# ESP32-S31 register map
Vendor: ESPRESSIF SYSTEMS (SHANGHAI) CO., LTD.; Series: ESP32 S-Series; File version: 1
CPU: RV32IMAFC r0p0, little endian, no MPU, FPU, 0 interrupt priority bits
Address unit: 32 bits
Registers are 32-bit, read-write, reset 0x0 unless marked. A register's access mark holds for its fields unless they carry their own. Offsets are from the block's base; [hi:lo] are bit positions.

## LP_PERI_PMS — LP_PERI_PMS Peripheral
Base 0x20706000
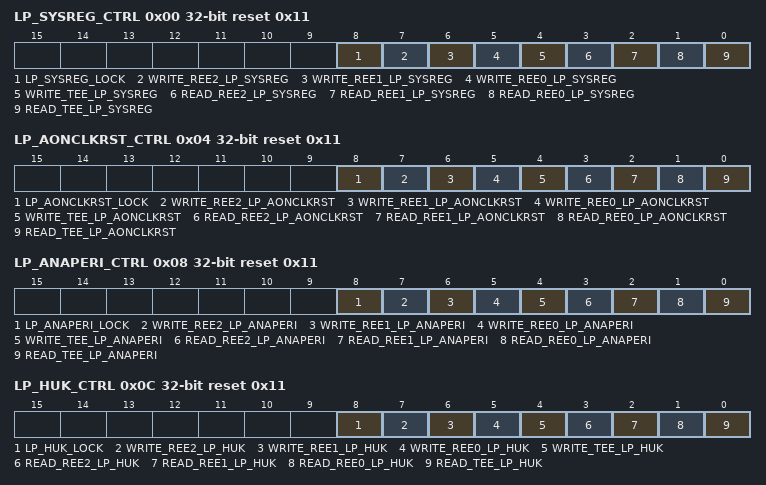
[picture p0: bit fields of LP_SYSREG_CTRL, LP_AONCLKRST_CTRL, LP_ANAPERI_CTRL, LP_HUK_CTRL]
0x00 LP_SYSREG_CTRL reset 0x11 — lp_sysreg read/write control register
  [8] LP_SYSREG_LOCK — Set 1 to lock lp_sysreg peri_apm configuration
  [7] WRITE_REE2_LP_SYSREG — Configures lp_sysreg registers write permission in ree2 mode.\\ 0: can not be write \\ 1: can be write \\
  [6] WRITE_REE1_LP_SYSREG — Configures lp_sysreg registers write permission in ree1 mode.\\ 0: can not be write \\ 1: can be write \\
  [5] WRITE_REE0_LP_SYSREG — Configures lp_sysreg registers write permission in ree0 mode.\\ 0: can not be write \\ 1: can be write \\
  [4] WRITE_TEE_LP_SYSREG — Configures lp_sysreg registers write permission in tee mode.\\ 0: can not be write \\ 1: can be write \\
  [3] READ_REE2_LP_SYSREG — Configures lp_sysreg registers read permission in ree2 mode.\\ 0: can not be read \\ 1: can be read \\
  [2] READ_REE1_LP_SYSREG — Configures lp_sysreg registers read permission in ree1 mode.\\ 0: can not be read \\ 1: can be read \\
  [1] READ_REE0_LP_SYSREG — Configures lp_sysreg registers read permission in ree0 mode.\\ 0: can not be read \\ 1: can be read \\
  [0] READ_TEE_LP_SYSREG — Configures lp_sysreg registers read permission in tee mode.\\ 0: can not be read \\ 1: can be read \\
0x04 LP_AONCLKRST_CTRL reset 0x11 — lp_aonclkrst read/write control register
  [8] LP_AONCLKRST_LOCK — Set 1 to lock lp_aonclkrst peri_apm configuration
  [7] WRITE_REE2_LP_AONCLKRST — Configures lp_aonclkrst registers write permission in ree2 mode.\\ 0: can not be write \\ 1: can be write \\
  [6] WRITE_REE1_LP_AONCLKRST — Configures lp_aonclkrst registers write permission in ree1 mode.\\ 0: can not be write \\ 1: can be write \\
  [5] WRITE_REE0_LP_AONCLKRST — Configures lp_aonclkrst registers write permission in ree0 mode.\\ 0: can not be write \\ 1: can be write \\
  [4] WRITE_TEE_LP_AONCLKRST — Configures lp_aonclkrst registers write permission in tee mode.\\ 0: can not be write \\ 1: can be write \\
  [3] READ_REE2_LP_AONCLKRST — Configures lp_aonclkrst registers read permission in ree2 mode.\\ 0: can not be read \\ 1: can be read \\
  [2] READ_REE1_LP_AONCLKRST — Configures lp_aonclkrst registers read permission in ree1 mode.\\ 0: can not be read \\ 1: can be read \\
  [1] READ_REE0_LP_AONCLKRST — Configures lp_aonclkrst registers read permission in ree0 mode.\\ 0: can not be read \\ 1: can be read \\
  [0] READ_TEE_LP_AONCLKRST — Configures lp_aonclkrst registers read permission in tee mode.\\ 0: can not be read \\ 1: can be read \\
0x08 LP_ANAPERI_CTRL reset 0x11 — lp_anaperi read/write control register
  [8] LP_ANAPERI_LOCK — Set 1 to lock lp_anaperi peri_apm configuration
  [7] WRITE_REE2_LP_ANAPERI — Configures lp_anaperi registers write permission in ree2 mode.\\ 0: can not be write \\ 1: can be write \\
  [6] WRITE_REE1_LP_ANAPERI — Configures lp_anaperi registers write permission in ree1 mode.\\ 0: can not be write \\ 1: can be write \\
  [5] WRITE_REE0_LP_ANAPERI — Configures lp_anaperi registers write permission in ree0 mode.\\ 0: can not be write \\ 1: can be write \\
  [4] WRITE_TEE_LP_ANAPERI — Configures lp_anaperi registers write permission in tee mode.\\ 0: can not be write \\ 1: can be write \\
  [3] READ_REE2_LP_ANAPERI — Configures lp_anaperi registers read permission in ree2 mode.\\ 0: can not be read \\ 1: can be read \\
  [2] READ_REE1_LP_ANAPERI — Configures lp_anaperi registers read permission in ree1 mode.\\ 0: can not be read \\ 1: can be read \\
  [1] READ_REE0_LP_ANAPERI — Configures lp_anaperi registers read permission in ree0 mode.\\ 0: can not be read \\ 1: can be read \\
  [0] READ_TEE_LP_ANAPERI — Configures lp_anaperi registers read permission in tee mode.\\ 0: can not be read \\ 1: can be read \\
0x0C LP_HUK_CTRL reset 0x11 — lp_huk read/write control register
  [8] LP_HUK_LOCK — Set 1 to lock lp_huk peri_apm configuration
  [7] WRITE_REE2_LP_HUK — Configures lp_huk registers write permission in ree2 mode.\\ 0: can not be write \\ 1: can be write \\
  [6] WRITE_REE1_LP_HUK — Configures lp_huk registers write permission in ree1 mode.\\ 0: can not be write \\ 1: can be write \\
  [5] WRITE_REE0_LP_HUK — Configures lp_huk registers write permission in ree0 mode.\\ 0: can not be write \\ 1: can be write \\
  [4] WRITE_TEE_LP_HUK — Configures lp_huk registers write permission in tee mode.\\ 0: can not be write \\ 1: can be write \\
  [3] READ_REE2_LP_HUK — Configures lp_huk registers read permission in ree2 mode.\\ 0: can not be read \\ 1: can be read \\
  [2] READ_REE1_LP_HUK — Configures lp_huk registers read permission in ree1 mode.\\ 0: can not be read \\ 1: can be read \\
  [1] READ_REE0_LP_HUK — Configures lp_huk registers read permission in ree0 mode.\\ 0: can not be read \\ 1: can be read \\
  [0] READ_TEE_LP_HUK — Configures lp_huk registers read permission in tee mode.\\ 0: can not be read \\ 1: can be read \\
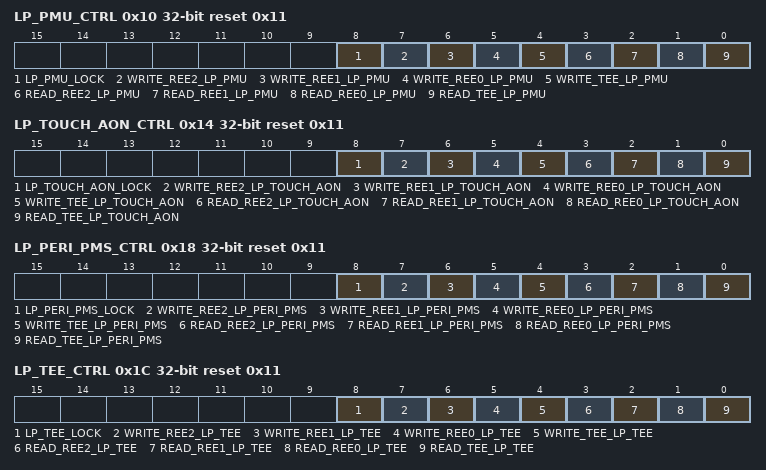
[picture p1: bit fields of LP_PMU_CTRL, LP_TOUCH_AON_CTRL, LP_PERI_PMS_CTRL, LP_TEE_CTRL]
0x10 LP_PMU_CTRL reset 0x11 — lp_pmu read/write control register
  [8] LP_PMU_LOCK — Set 1 to lock lp_pmu peri_apm configuration
  [7] WRITE_REE2_LP_PMU — Configures lp_pmu registers write permission in ree2 mode.\\ 0: can not be write \\ 1: can be write \\
  [6] WRITE_REE1_LP_PMU — Configures lp_pmu registers write permission in ree1 mode.\\ 0: can not be write \\ 1: can be write \\
  [5] WRITE_REE0_LP_PMU — Configures lp_pmu registers write permission in ree0 mode.\\ 0: can not be write \\ 1: can be write \\
  [4] WRITE_TEE_LP_PMU — Configures lp_pmu registers write permission in tee mode.\\ 0: can not be write \\ 1: can be write \\
  [3] READ_REE2_LP_PMU — Configures lp_pmu registers read permission in ree2 mode.\\ 0: can not be read \\ 1: can be read \\
  [2] READ_REE1_LP_PMU — Configures lp_pmu registers read permission in ree1 mode.\\ 0: can not be read \\ 1: can be read \\
  [1] READ_REE0_LP_PMU — Configures lp_pmu registers read permission in ree0 mode.\\ 0: can not be read \\ 1: can be read \\
  [0] READ_TEE_LP_PMU — Configures lp_pmu registers read permission in tee mode.\\ 0: can not be read \\ 1: can be read \\
0x14 LP_TOUCH_AON_CTRL reset 0x11 — lp_touch_aon read/write control register
  [8] LP_TOUCH_AON_LOCK — Set 1 to lock lp_touch_aon peri_apm configuration
  [7] WRITE_REE2_LP_TOUCH_AON — Configures lp_touch_aon registers write permission in ree2 mode.\\ 0: can not be write \\ 1: can be write \\
  [6] WRITE_REE1_LP_TOUCH_AON — Configures lp_touch_aon registers write permission in ree1 mode.\\ 0: can not be write \\ 1: can be write \\
  [5] WRITE_REE0_LP_TOUCH_AON — Configures lp_touch_aon registers write permission in ree0 mode.\\ 0: can not be write \\ 1: can be write \\
  [4] WRITE_TEE_LP_TOUCH_AON — Configures lp_touch_aon registers write permission in tee mode.\\ 0: can not be write \\ 1: can be write \\
  [3] READ_REE2_LP_TOUCH_AON — Configures lp_touch_aon registers read permission in ree2 mode.\\ 0: can not be read \\ 1: can be read \\
  [2] READ_REE1_LP_TOUCH_AON — Configures lp_touch_aon registers read permission in ree1 mode.\\ 0: can not be read \\ 1: can be read \\
  [1] READ_REE0_LP_TOUCH_AON — Configures lp_touch_aon registers read permission in ree0 mode.\\ 0: can not be read \\ 1: can be read \\
  [0] READ_TEE_LP_TOUCH_AON — Configures lp_touch_aon registers read permission in tee mode.\\ 0: can not be read \\ 1: can be read \\
0x18 LP_PERI_PMS_CTRL access per field reset 0x11 — lp_peri_pms read/write control register
  [8] LP_PERI_PMS_LOCK rw — Set 1 to lock lp_peri_pms peri_apm configuration
  [7] WRITE_REE2_LP_PERI_PMS ro — Configures lp_peri_pms registers write permission in ree2 mode.\\ 0: can not be write \\ 1: can be write \\
  [6] WRITE_REE1_LP_PERI_PMS ro — Configures lp_peri_pms registers write permission in ree1 mode.\\ 0: can not be write \\ 1: can be write \\
  [5] WRITE_REE0_LP_PERI_PMS ro — Configures lp_peri_pms registers write permission in ree0 mode.\\ 0: can not be write \\ 1: can be write \\
  [4] WRITE_TEE_LP_PERI_PMS rw — Configures lp_peri_pms registers write permission in tee mode.\\ 0: can not be write \\ 1: can be write \\
  [3] READ_REE2_LP_PERI_PMS ro — Configures lp_peri_pms registers read permission in ree2 mode.\\ 0: can not be read \\ 1: can be read \\
  [2] READ_REE1_LP_PERI_PMS ro — Configures lp_peri_pms registers read permission in ree1 mode.\\ 0: can not be read \\ 1: can be read \\
  [1] READ_REE0_LP_PERI_PMS ro — Configures lp_peri_pms registers read permission in ree0 mode.\\ 0: can not be read \\ 1: can be read \\
  [0] READ_TEE_LP_PERI_PMS rw — Configures lp_peri_pms registers read permission in tee mode.\\ 0: can not be read \\ 1: can be read \\
0x1C LP_TEE_CTRL access per field reset 0x11 — lp_tee read/write control register
  [8] LP_TEE_LOCK rw — Set 1 to lock lp_tee peri_apm configuration
  [7] WRITE_REE2_LP_TEE ro — Configures lp_tee registers write permission in ree2 mode.\\ 0: can not be write \\ 1: can be write \\
  [6] WRITE_REE1_LP_TEE ro — Configures lp_tee registers write permission in ree1 mode.\\ 0: can not be write \\ 1: can be write \\
  [5] WRITE_REE0_LP_TEE ro — Configures lp_tee registers write permission in ree0 mode.\\ 0: can not be write \\ 1: can be write \\
  [4] WRITE_TEE_LP_TEE rw — Configures lp_tee registers write permission in tee mode.\\ 0: can not be write \\ 1: can be write \\
  [3] READ_REE2_LP_TEE ro — Configures lp_tee registers read permission in ree2 mode.\\ 0: can not be read \\ 1: can be read \\
  [2] READ_REE1_LP_TEE ro — Configures lp_tee registers read permission in ree1 mode.\\ 0: can not be read \\ 1: can be read \\
  [1] READ_REE0_LP_TEE ro — Configures lp_tee registers read permission in ree0 mode.\\ 0: can not be read \\ 1: can be read \\
  [0] READ_TEE_LP_TEE rw — Configures lp_tee registers read permission in tee mode.\\ 0: can not be read \\ 1: can be read \\
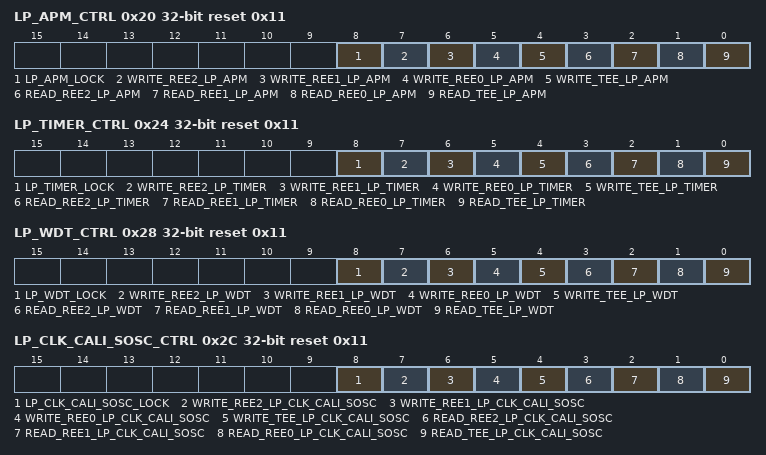
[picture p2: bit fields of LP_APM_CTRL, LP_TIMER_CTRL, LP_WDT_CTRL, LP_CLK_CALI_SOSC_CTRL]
0x20 LP_APM_CTRL access per field reset 0x11 — lp_apm read/write control register
  [8] LP_APM_LOCK rw — Set 1 to lock lp_apm peri_apm configuration
  [7] WRITE_REE2_LP_APM ro — Configures lp_apm registers write permission in ree2 mode.\\ 0: can not be write \\ 1: can be write \\
  [6] WRITE_REE1_LP_APM ro — Configures lp_apm registers write permission in ree1 mode.\\ 0: can not be write \\ 1: can be write \\
  [5] WRITE_REE0_LP_APM ro — Configures lp_apm registers write permission in ree0 mode.\\ 0: can not be write \\ 1: can be write \\
  [4] WRITE_TEE_LP_APM rw — Configures lp_apm registers write permission in tee mode.\\ 0: can not be write \\ 1: can be write \\
  [3] READ_REE2_LP_APM ro — Configures lp_apm registers read permission in ree2 mode.\\ 0: can not be read \\ 1: can be read \\
  [2] READ_REE1_LP_APM ro — Configures lp_apm registers read permission in ree1 mode.\\ 0: can not be read \\ 1: can be read \\
  [1] READ_REE0_LP_APM ro — Configures lp_apm registers read permission in ree0 mode.\\ 0: can not be read \\ 1: can be read \\
  [0] READ_TEE_LP_APM rw — Configures lp_apm registers read permission in tee mode.\\ 0: can not be read \\ 1: can be read \\
0x24 LP_TIMER_CTRL reset 0x11 — lp_timer read/write control register
  [8] LP_TIMER_LOCK — Set 1 to lock lp_timer peri_apm configuration
  [7] WRITE_REE2_LP_TIMER — Configures lp_timer registers write permission in ree2 mode.\\ 0: can not be write \\ 1: can be write \\
  [6] WRITE_REE1_LP_TIMER — Configures lp_timer registers write permission in ree1 mode.\\ 0: can not be write \\ 1: can be write \\
  [5] WRITE_REE0_LP_TIMER — Configures lp_timer registers write permission in ree0 mode.\\ 0: can not be write \\ 1: can be write \\
  [4] WRITE_TEE_LP_TIMER — Configures lp_timer registers write permission in tee mode.\\ 0: can not be write \\ 1: can be write \\
  [3] READ_REE2_LP_TIMER — Configures lp_timer registers read permission in ree2 mode.\\ 0: can not be read \\ 1: can be read \\
  [2] READ_REE1_LP_TIMER — Configures lp_timer registers read permission in ree1 mode.\\ 0: can not be read \\ 1: can be read \\
  [1] READ_REE0_LP_TIMER — Configures lp_timer registers read permission in ree0 mode.\\ 0: can not be read \\ 1: can be read \\
  [0] READ_TEE_LP_TIMER — Configures lp_timer registers read permission in tee mode.\\ 0: can not be read \\ 1: can be read \\
0x28 LP_WDT_CTRL reset 0x11 — lp_wdt read/write control register
  [8] LP_WDT_LOCK — Set 1 to lock lp_wdt peri_apm configuration
  [7] WRITE_REE2_LP_WDT — Configures lp_wdt registers write permission in ree2 mode.\\ 0: can not be write \\ 1: can be write \\
  [6] WRITE_REE1_LP_WDT — Configures lp_wdt registers write permission in ree1 mode.\\ 0: can not be write \\ 1: can be write \\
  [5] WRITE_REE0_LP_WDT — Configures lp_wdt registers write permission in ree0 mode.\\ 0: can not be write \\ 1: can be write \\
  [4] WRITE_TEE_LP_WDT — Configures lp_wdt registers write permission in tee mode.\\ 0: can not be write \\ 1: can be write \\
  [3] READ_REE2_LP_WDT — Configures lp_wdt registers read permission in ree2 mode.\\ 0: can not be read \\ 1: can be read \\
  [2] READ_REE1_LP_WDT — Configures lp_wdt registers read permission in ree1 mode.\\ 0: can not be read \\ 1: can be read \\
  [1] READ_REE0_LP_WDT — Configures lp_wdt registers read permission in ree0 mode.\\ 0: can not be read \\ 1: can be read \\
  [0] READ_TEE_LP_WDT — Configures lp_wdt registers read permission in tee mode.\\ 0: can not be read \\ 1: can be read \\
0x2C LP_CLK_CALI_SOSC_CTRL reset 0x11 — lp_clk_cali_sosc read/write control register
  [8] LP_CLK_CALI_SOSC_LOCK — Set 1 to lock lp_clk_cali_sosc peri_apm configuration
  [7] WRITE_REE2_LP_CLK_CALI_SOSC — Configures lp_clk_cali_sosc registers write permission in ree2 mode.\\ 0: can not be write \\ 1: can be write \\
  [6] WRITE_REE1_LP_CLK_CALI_SOSC — Configures lp_clk_cali_sosc registers write permission in ree1 mode.\\ 0: can not be write \\ 1: can be write \\
  [5] WRITE_REE0_LP_CLK_CALI_SOSC — Configures lp_clk_cali_sosc registers write permission in ree0 mode.\\ 0: can not be write \\ 1: can be write \\
  [4] WRITE_TEE_LP_CLK_CALI_SOSC — Configures lp_clk_cali_sosc registers write permission in tee mode.\\ 0: can not be write \\ 1: can be write \\
  [3] READ_REE2_LP_CLK_CALI_SOSC — Configures lp_clk_cali_sosc registers read permission in ree2 mode.\\ 0: can not be read \\ 1: can be read \\
  [2] READ_REE1_LP_CLK_CALI_SOSC — Configures lp_clk_cali_sosc registers read permission in ree1 mode.\\ 0: can not be read \\ 1: can be read \\
  [1] READ_REE0_LP_CLK_CALI_SOSC — Configures lp_clk_cali_sosc registers read permission in ree0 mode.\\ 0: can not be read \\ 1: can be read \\
  [0] READ_TEE_LP_CLK_CALI_SOSC — Configures lp_clk_cali_sosc registers read permission in tee mode.\\ 0: can not be read \\ 1: can be read \\
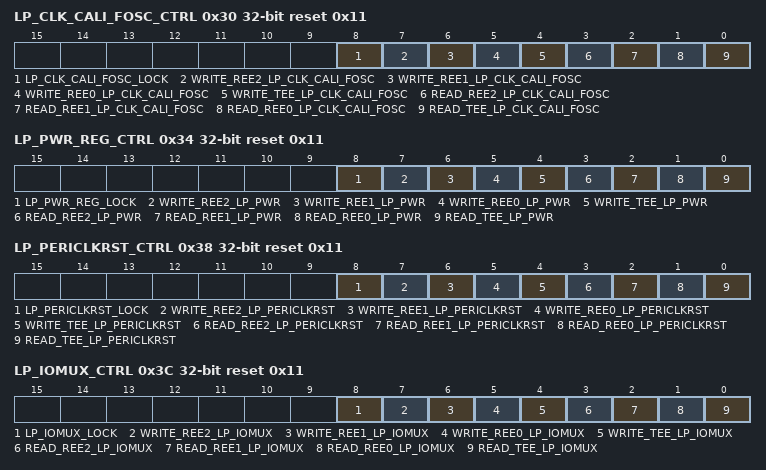
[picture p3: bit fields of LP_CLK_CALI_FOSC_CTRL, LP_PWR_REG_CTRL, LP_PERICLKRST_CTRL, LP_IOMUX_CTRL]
0x30 LP_CLK_CALI_FOSC_CTRL reset 0x11 — lp_clk_cali_fosc read/write control register
  [8] LP_CLK_CALI_FOSC_LOCK — Set 1 to lock lp_clk_cali_fosc peri_apm configuration
  [7] WRITE_REE2_LP_CLK_CALI_FOSC — Configures lp_clk_cali_fosc registers write permission in ree2 mode.\\ 0: can not be write \\ 1: can be write \\
  [6] WRITE_REE1_LP_CLK_CALI_FOSC — Configures lp_clk_cali_fosc registers write permission in ree1 mode.\\ 0: can not be write \\ 1: can be write \\
  [5] WRITE_REE0_LP_CLK_CALI_FOSC — Configures lp_clk_cali_fosc registers write permission in ree0 mode.\\ 0: can not be write \\ 1: can be write \\
  [4] WRITE_TEE_LP_CLK_CALI_FOSC — Configures lp_clk_cali_fosc registers write permission in tee mode.\\ 0: can not be write \\ 1: can be write \\
  [3] READ_REE2_LP_CLK_CALI_FOSC — Configures lp_clk_cali_fosc registers read permission in ree2 mode.\\ 0: can not be read \\ 1: can be read \\
  [2] READ_REE1_LP_CLK_CALI_FOSC — Configures lp_clk_cali_fosc registers read permission in ree1 mode.\\ 0: can not be read \\ 1: can be read \\
  [1] READ_REE0_LP_CLK_CALI_FOSC — Configures lp_clk_cali_fosc registers read permission in ree0 mode.\\ 0: can not be read \\ 1: can be read \\
  [0] READ_TEE_LP_CLK_CALI_FOSC — Configures lp_clk_cali_fosc registers read permission in tee mode.\\ 0: can not be read \\ 1: can be read \\
0x34 LP_PWR_REG_CTRL reset 0x11 — lp_pwr_reg read/write control register
  [8] LP_PWR_REG_LOCK — Set 1 to lock lp_pwr_reg peri_apm configuration
  [7] WRITE_REE2_LP_PWR — Configures lp_pwr_reg registers write permission in ree2 mode.\\ 0: can not be write \\ 1: can be write \\
  [6] WRITE_REE1_LP_PWR — Configures lp_pwr_reg registers write permission in ree1 mode.\\ 0: can not be write \\ 1: can be write \\
  [5] WRITE_REE0_LP_PWR — Configures lp_pwr_reg registers write permission in ree0 mode.\\ 0: can not be write \\ 1: can be write \\
  [4] WRITE_TEE_LP_PWR — Configures lp_pwr_reg registers write permission in tee mode.\\ 0: can not be write \\ 1: can be write \\
  [3] READ_REE2_LP_PWR — Configures lp_pwr_reg registers read permission in ree2 mode.\\ 0: can not be read \\ 1: can be read \\
  [2] READ_REE1_LP_PWR — Configures lp_pwr_reg registers read permission in ree1 mode.\\ 0: can not be read \\ 1: can be read \\
  [1] READ_REE0_LP_PWR — Configures lp_pwr_reg registers read permission in ree0 mode.\\ 0: can not be read \\ 1: can be read \\
  [0] READ_TEE_LP_PWR — Configures lp_pwr_reg registers read permission in tee mode.\\ 0: can not be read \\ 1: can be read \\
0x38 LP_PERICLKRST_CTRL reset 0x11 — lp_periclkrst read/write control register
  [8] LP_PERICLKRST_LOCK — Set 1 to lock lp_periclkrst peri_apm configuration
  [7] WRITE_REE2_LP_PERICLKRST — Configures lp_periclkrst registers write permission in ree2 mode.\\ 0: can not be write \\ 1: can be write \\
  [6] WRITE_REE1_LP_PERICLKRST — Configures lp_periclkrst registers write permission in ree1 mode.\\ 0: can not be write \\ 1: can be write \\
  [5] WRITE_REE0_LP_PERICLKRST — Configures lp_periclkrst registers write permission in ree0 mode.\\ 0: can not be write \\ 1: can be write \\
  [4] WRITE_TEE_LP_PERICLKRST — Configures lp_periclkrst registers write permission in tee mode.\\ 0: can not be write \\ 1: can be write \\
  [3] READ_REE2_LP_PERICLKRST — Configures lp_periclkrst registers read permission in ree2 mode.\\ 0: can not be read \\ 1: can be read \\
  [2] READ_REE1_LP_PERICLKRST — Configures lp_periclkrst registers read permission in ree1 mode.\\ 0: can not be read \\ 1: can be read \\
  [1] READ_REE0_LP_PERICLKRST — Configures lp_periclkrst registers read permission in ree0 mode.\\ 0: can not be read \\ 1: can be read \\
  [0] READ_TEE_LP_PERICLKRST — Configures lp_periclkrst registers read permission in tee mode.\\ 0: can not be read \\ 1: can be read \\
0x3C LP_IOMUX_CTRL reset 0x11 — lp_iomux read/write control register
  [8] LP_IOMUX_LOCK — Set 1 to lock lp_iomux peri_apm configuration
  [7] WRITE_REE2_LP_IOMUX — Configures lp_iomux registers write permission in ree2 mode.\\ 0: can not be write \\ 1: can be write \\
  [6] WRITE_REE1_LP_IOMUX — Configures lp_iomux registers write permission in ree1 mode.\\ 0: can not be write \\ 1: can be write \\
  [5] WRITE_REE0_LP_IOMUX — Configures lp_iomux registers write permission in ree0 mode.\\ 0: can not be write \\ 1: can be write \\
  [4] WRITE_TEE_LP_IOMUX — Configures lp_iomux registers write permission in tee mode.\\ 0: can not be write \\ 1: can be write \\
  [3] READ_REE2_LP_IOMUX — Configures lp_iomux registers read permission in ree2 mode.\\ 0: can not be read \\ 1: can be read \\
  [2] READ_REE1_LP_IOMUX — Configures lp_iomux registers read permission in ree1 mode.\\ 0: can not be read \\ 1: can be read \\
  [1] READ_REE0_LP_IOMUX — Configures lp_iomux registers read permission in ree0 mode.\\ 0: can not be read \\ 1: can be read \\
  [0] READ_TEE_LP_IOMUX — Configures lp_iomux registers read permission in tee mode.\\ 0: can not be read \\ 1: can be read \\
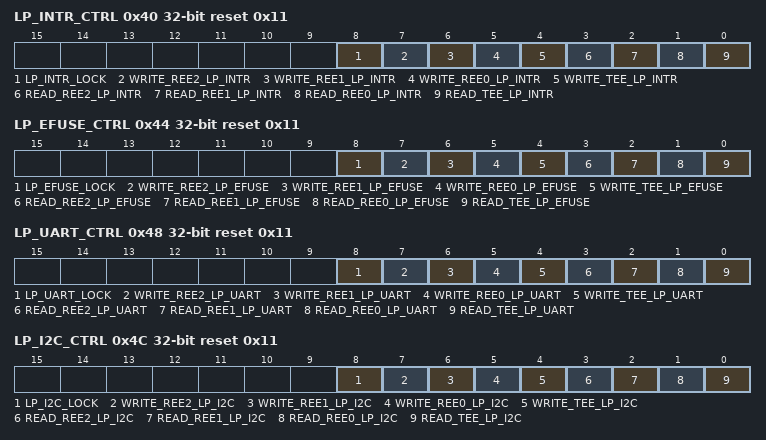
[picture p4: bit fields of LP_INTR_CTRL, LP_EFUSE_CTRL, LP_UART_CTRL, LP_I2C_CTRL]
0x40 LP_INTR_CTRL reset 0x11 — lp_intr read/write control register
  [8] LP_INTR_LOCK — Set 1 to lock lp_intr peri_apm configuration
  [7] WRITE_REE2_LP_INTR — Configures lp_intr registers write permission in ree2 mode.\\ 0: can not be write \\ 1: can be write \\
  [6] WRITE_REE1_LP_INTR — Configures lp_intr registers write permission in ree1 mode.\\ 0: can not be write \\ 1: can be write \\
  [5] WRITE_REE0_LP_INTR — Configures lp_intr registers write permission in ree0 mode.\\ 0: can not be write \\ 1: can be write \\
  [4] WRITE_TEE_LP_INTR — Configures lp_intr registers write permission in tee mode.\\ 0: can not be write \\ 1: can be write \\
  [3] READ_REE2_LP_INTR — Configures lp_intr registers read permission in ree2 mode.\\ 0: can not be read \\ 1: can be read \\
  [2] READ_REE1_LP_INTR — Configures lp_intr registers read permission in ree1 mode.\\ 0: can not be read \\ 1: can be read \\
  [1] READ_REE0_LP_INTR — Configures lp_intr registers read permission in ree0 mode.\\ 0: can not be read \\ 1: can be read \\
  [0] READ_TEE_LP_INTR — Configures lp_intr registers read permission in tee mode.\\ 0: can not be read \\ 1: can be read \\
0x44 LP_EFUSE_CTRL reset 0x11 — lp_efuse read/write control register
  [8] LP_EFUSE_LOCK — Set 1 to lock lp_efuse peri_apm configuration
  [7] WRITE_REE2_LP_EFUSE — Configures lp_efuse registers write permission in ree2 mode.\\ 0: can not be write \\ 1: can be write \\
  [6] WRITE_REE1_LP_EFUSE — Configures lp_efuse registers write permission in ree1 mode.\\ 0: can not be write \\ 1: can be write \\
  [5] WRITE_REE0_LP_EFUSE — Configures lp_efuse registers write permission in ree0 mode.\\ 0: can not be write \\ 1: can be write \\
  [4] WRITE_TEE_LP_EFUSE — Configures lp_efuse registers write permission in tee mode.\\ 0: can not be write \\ 1: can be write \\
  [3] READ_REE2_LP_EFUSE — Configures lp_efuse registers read permission in ree2 mode.\\ 0: can not be read \\ 1: can be read \\
  [2] READ_REE1_LP_EFUSE — Configures lp_efuse registers read permission in ree1 mode.\\ 0: can not be read \\ 1: can be read \\
  [1] READ_REE0_LP_EFUSE — Configures lp_efuse registers read permission in ree0 mode.\\ 0: can not be read \\ 1: can be read \\
  [0] READ_TEE_LP_EFUSE — Configures lp_efuse registers read permission in tee mode.\\ 0: can not be read \\ 1: can be read \\
0x48 LP_UART_CTRL reset 0x11 — lp_uart read/write control register
  [8] LP_UART_LOCK — Set 1 to lock lp_uart peri_apm configuration
  [7] WRITE_REE2_LP_UART — Configures lp_uart registers write permission in ree2 mode.\\ 0: can not be write \\ 1: can be write \\
  [6] WRITE_REE1_LP_UART — Configures lp_uart registers write permission in ree1 mode.\\ 0: can not be write \\ 1: can be write \\
  [5] WRITE_REE0_LP_UART — Configures lp_uart registers write permission in ree0 mode.\\ 0: can not be write \\ 1: can be write \\
  [4] WRITE_TEE_LP_UART — Configures lp_uart registers write permission in tee mode.\\ 0: can not be write \\ 1: can be write \\
  [3] READ_REE2_LP_UART — Configures lp_uart registers read permission in ree2 mode.\\ 0: can not be read \\ 1: can be read \\
  [2] READ_REE1_LP_UART — Configures lp_uart registers read permission in ree1 mode.\\ 0: can not be read \\ 1: can be read \\
  [1] READ_REE0_LP_UART — Configures lp_uart registers read permission in ree0 mode.\\ 0: can not be read \\ 1: can be read \\
  [0] READ_TEE_LP_UART — Configures lp_uart registers read permission in tee mode.\\ 0: can not be read \\ 1: can be read \\
0x4C LP_I2C_CTRL reset 0x11 — lp_i2c read/write control register
  [8] LP_I2C_LOCK — Set 1 to lock lp_i2c peri_apm configuration
  [7] WRITE_REE2_LP_I2C — Configures lp_i2c registers write permission in ree2 mode.\\ 0: can not be write \\ 1: can be write \\
  [6] WRITE_REE1_LP_I2C — Configures lp_i2c registers write permission in ree1 mode.\\ 0: can not be write \\ 1: can be write \\
  [5] WRITE_REE0_LP_I2C — Configures lp_i2c registers write permission in ree0 mode.\\ 0: can not be write \\ 1: can be write \\
  [4] WRITE_TEE_LP_I2C — Configures lp_i2c registers write permission in tee mode.\\ 0: can not be write \\ 1: can be write \\
  [3] READ_REE2_LP_I2C — Configures lp_i2c registers read permission in ree2 mode.\\ 0: can not be read \\ 1: can be read \\
  [2] READ_REE1_LP_I2C — Configures lp_i2c registers read permission in ree1 mode.\\ 0: can not be read \\ 1: can be read \\
  [1] READ_REE0_LP_I2C — Configures lp_i2c registers read permission in ree0 mode.\\ 0: can not be read \\ 1: can be read \\
  [0] READ_TEE_LP_I2C — Configures lp_i2c registers read permission in tee mode.\\ 0: can not be read \\ 1: can be read \\
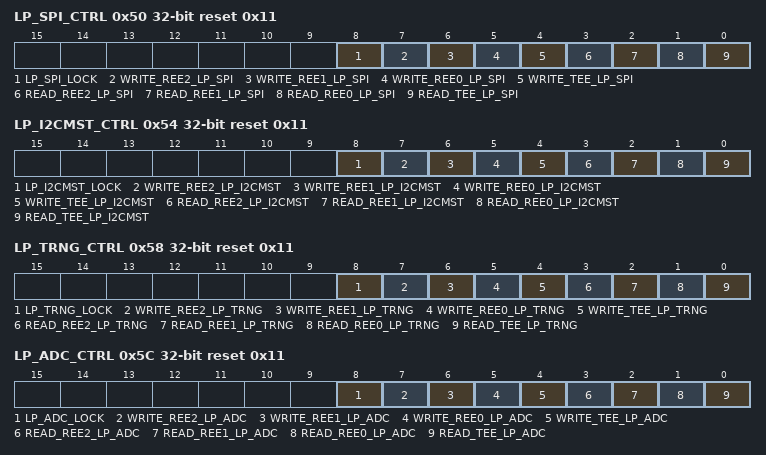
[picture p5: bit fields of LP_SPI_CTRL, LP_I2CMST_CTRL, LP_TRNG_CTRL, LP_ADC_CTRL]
0x50 LP_SPI_CTRL reset 0x11 — lp_spi read/write control register
  [8] LP_SPI_LOCK — Set 1 to lock lp_spi peri_apm configuration
  [7] WRITE_REE2_LP_SPI — Configures lp_spi registers write permission in ree2 mode.\\ 0: can not be write \\ 1: can be write \\
  [6] WRITE_REE1_LP_SPI — Configures lp_spi registers write permission in ree1 mode.\\ 0: can not be write \\ 1: can be write \\
  [5] WRITE_REE0_LP_SPI — Configures lp_spi registers write permission in ree0 mode.\\ 0: can not be write \\ 1: can be write \\
  [4] WRITE_TEE_LP_SPI — Configures lp_spi registers write permission in tee mode.\\ 0: can not be write \\ 1: can be write \\
  [3] READ_REE2_LP_SPI — Configures lp_spi registers read permission in ree2 mode.\\ 0: can not be read \\ 1: can be read \\
  [2] READ_REE1_LP_SPI — Configures lp_spi registers read permission in ree1 mode.\\ 0: can not be read \\ 1: can be read \\
  [1] READ_REE0_LP_SPI — Configures lp_spi registers read permission in ree0 mode.\\ 0: can not be read \\ 1: can be read \\
  [0] READ_TEE_LP_SPI — Configures lp_spi registers read permission in tee mode.\\ 0: can not be read \\ 1: can be read \\
0x54 LP_I2CMST_CTRL reset 0x11 — lp_i2cmst read/write control register
  [8] LP_I2CMST_LOCK — Set 1 to lock lp_i2cmst peri_apm configuration
  [7] WRITE_REE2_LP_I2CMST — Configures lp_i2cmst registers write permission in ree2 mode.\\ 0: can not be write \\ 1: can be write \\
  [6] WRITE_REE1_LP_I2CMST — Configures lp_i2cmst registers write permission in ree1 mode.\\ 0: can not be write \\ 1: can be write \\
  [5] WRITE_REE0_LP_I2CMST — Configures lp_i2cmst registers write permission in ree0 mode.\\ 0: can not be write \\ 1: can be write \\
  [4] WRITE_TEE_LP_I2CMST — Configures lp_i2cmst registers write permission in tee mode.\\ 0: can not be write \\ 1: can be write \\
  [3] READ_REE2_LP_I2CMST — Configures lp_i2cmst registers read permission in ree2 mode.\\ 0: can not be read \\ 1: can be read \\
  [2] READ_REE1_LP_I2CMST — Configures lp_i2cmst registers read permission in ree1 mode.\\ 0: can not be read \\ 1: can be read \\
  [1] READ_REE0_LP_I2CMST — Configures lp_i2cmst registers read permission in ree0 mode.\\ 0: can not be read \\ 1: can be read \\
  [0] READ_TEE_LP_I2CMST — Configures lp_i2cmst registers read permission in tee mode.\\ 0: can not be read \\ 1: can be read \\
0x58 LP_TRNG_CTRL reset 0x11 — lp_trng read/write control register
  [8] LP_TRNG_LOCK — Set 1 to lock lp_trng peri_apm configuration
  [7] WRITE_REE2_LP_TRNG — Configures lp_trng registers write permission in ree2 mode.\\ 0: can not be write \\ 1: can be write \\
  [6] WRITE_REE1_LP_TRNG — Configures lp_trng registers write permission in ree1 mode.\\ 0: can not be write \\ 1: can be write \\
  [5] WRITE_REE0_LP_TRNG — Configures lp_trng registers write permission in ree0 mode.\\ 0: can not be write \\ 1: can be write \\
  [4] WRITE_TEE_LP_TRNG — Configures lp_trng registers write permission in tee mode.\\ 0: can not be write \\ 1: can be write \\
  [3] READ_REE2_LP_TRNG — Configures lp_trng registers read permission in ree2 mode.\\ 0: can not be read \\ 1: can be read \\
  [2] READ_REE1_LP_TRNG — Configures lp_trng registers read permission in ree1 mode.\\ 0: can not be read \\ 1: can be read \\
  [1] READ_REE0_LP_TRNG — Configures lp_trng registers read permission in ree0 mode.\\ 0: can not be read \\ 1: can be read \\
  [0] READ_TEE_LP_TRNG — Configures lp_trng registers read permission in tee mode.\\ 0: can not be read \\ 1: can be read \\
0x5C LP_ADC_CTRL reset 0x11 — lp_adc read/write control register
  [8] LP_ADC_LOCK — Set 1 to lock lp_adc peri_apm configuration
  [7] WRITE_REE2_LP_ADC — Configures lp_adc registers write permission in ree2 mode.\\ 0: can not be write \\ 1: can be write \\
  [6] WRITE_REE1_LP_ADC — Configures lp_adc registers write permission in ree1 mode.\\ 0: can not be write \\ 1: can be write \\
  [5] WRITE_REE0_LP_ADC — Configures lp_adc registers write permission in ree0 mode.\\ 0: can not be write \\ 1: can be write \\
  [4] WRITE_TEE_LP_ADC — Configures lp_adc registers write permission in tee mode.\\ 0: can not be write \\ 1: can be write \\
  [3] READ_REE2_LP_ADC — Configures lp_adc registers read permission in ree2 mode.\\ 0: can not be read \\ 1: can be read \\
  [2] READ_REE1_LP_ADC — Configures lp_adc registers read permission in ree1 mode.\\ 0: can not be read \\ 1: can be read \\
  [1] READ_REE0_LP_ADC — Configures lp_adc registers read permission in ree0 mode.\\ 0: can not be read \\ 1: can be read \\
  [0] READ_TEE_LP_ADC — Configures lp_adc registers read permission in tee mode.\\ 0: can not be read \\ 1: can be read \\
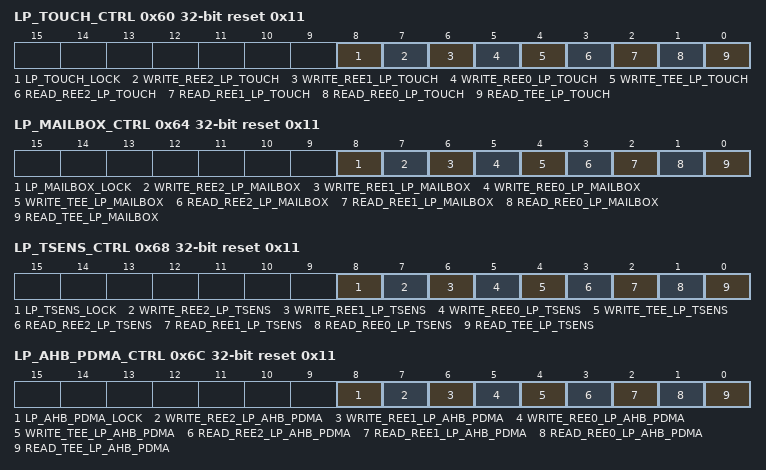
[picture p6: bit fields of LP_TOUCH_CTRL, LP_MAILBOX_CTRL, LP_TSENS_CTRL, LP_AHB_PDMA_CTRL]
0x60 LP_TOUCH_CTRL reset 0x11 — lp_touch read/write control register
  [8] LP_TOUCH_LOCK — Set 1 to lock lp_touch peri_apm configuration
  [7] WRITE_REE2_LP_TOUCH — Configures lp_touch registers write permission in ree2 mode.\\ 0: can not be write \\ 1: can be write \\
  [6] WRITE_REE1_LP_TOUCH — Configures lp_touch registers write permission in ree1 mode.\\ 0: can not be write \\ 1: can be write \\
  [5] WRITE_REE0_LP_TOUCH — Configures lp_touch registers write permission in ree0 mode.\\ 0: can not be write \\ 1: can be write \\
  [4] WRITE_TEE_LP_TOUCH — Configures lp_touch registers write permission in tee mode.\\ 0: can not be write \\ 1: can be write \\
  [3] READ_REE2_LP_TOUCH — Configures lp_touch registers read permission in ree2 mode.\\ 0: can not be read \\ 1: can be read \\
  [2] READ_REE1_LP_TOUCH — Configures lp_touch registers read permission in ree1 mode.\\ 0: can not be read \\ 1: can be read \\
  [1] READ_REE0_LP_TOUCH — Configures lp_touch registers read permission in ree0 mode.\\ 0: can not be read \\ 1: can be read \\
  [0] READ_TEE_LP_TOUCH — Configures lp_touch registers read permission in tee mode.\\ 0: can not be read \\ 1: can be read \\
0x64 LP_MAILBOX_CTRL reset 0x11 — lp_mailbox read/write control register
  [8] LP_MAILBOX_LOCK — Set 1 to lock lp_mailbox peri_apm configuration
  [7] WRITE_REE2_LP_MAILBOX — Configures lp_mailbox registers write permission in ree2 mode.\\ 0: can not be write \\ 1: can be write \\
  [6] WRITE_REE1_LP_MAILBOX — Configures lp_mailbox registers write permission in ree1 mode.\\ 0: can not be write \\ 1: can be write \\
  [5] WRITE_REE0_LP_MAILBOX — Configures lp_mailbox registers write permission in ree0 mode.\\ 0: can not be write \\ 1: can be write \\
  [4] WRITE_TEE_LP_MAILBOX — Configures lp_mailbox registers write permission in tee mode.\\ 0: can not be write \\ 1: can be write \\
  [3] READ_REE2_LP_MAILBOX — Configures lp_mailbox registers read permission in ree2 mode.\\ 0: can not be read \\ 1: can be read \\
  [2] READ_REE1_LP_MAILBOX — Configures lp_mailbox registers read permission in ree1 mode.\\ 0: can not be read \\ 1: can be read \\
  [1] READ_REE0_LP_MAILBOX — Configures lp_mailbox registers read permission in ree0 mode.\\ 0: can not be read \\ 1: can be read \\
  [0] READ_TEE_LP_MAILBOX — Configures lp_mailbox registers read permission in tee mode.\\ 0: can not be read \\ 1: can be read \\
0x68 LP_TSENS_CTRL reset 0x11 — lp_tsens read/write control register
  [8] LP_TSENS_LOCK — Set 1 to lock lp_tsens peri_apm configuration
  [7] WRITE_REE2_LP_TSENS — Configures lp_tsens registers write permission in ree2 mode.\\ 0: can not be write \\ 1: can be write \\
  [6] WRITE_REE1_LP_TSENS — Configures lp_tsens registers write permission in ree1 mode.\\ 0: can not be write \\ 1: can be write \\
  [5] WRITE_REE0_LP_TSENS — Configures lp_tsens registers write permission in ree0 mode.\\ 0: can not be write \\ 1: can be write \\
  [4] WRITE_TEE_LP_TSENS — Configures lp_tsens registers write permission in tee mode.\\ 0: can not be write \\ 1: can be write \\
  [3] READ_REE2_LP_TSENS — Configures lp_tsens registers read permission in ree2 mode.\\ 0: can not be read \\ 1: can be read \\
  [2] READ_REE1_LP_TSENS — Configures lp_tsens registers read permission in ree1 mode.\\ 0: can not be read \\ 1: can be read \\
  [1] READ_REE0_LP_TSENS — Configures lp_tsens registers read permission in ree0 mode.\\ 0: can not be read \\ 1: can be read \\
  [0] READ_TEE_LP_TSENS — Configures lp_tsens registers read permission in tee mode.\\ 0: can not be read \\ 1: can be read \\
0x6C LP_AHB_PDMA_CTRL reset 0x11 — lp_ahb_pdma read/write control register
  [8] LP_AHB_PDMA_LOCK — Set 1 to lock lp_ahb_pdma peri_apm configuration
  [7] WRITE_REE2_LP_AHB_PDMA — Configures lp_ahb_pdma registers write permission in ree2 mode.\\ 0: can not be write \\ 1: can be write \\
  [6] WRITE_REE1_LP_AHB_PDMA — Configures lp_ahb_pdma registers write permission in ree1 mode.\\ 0: can not be write \\ 1: can be write \\
  [5] WRITE_REE0_LP_AHB_PDMA — Configures lp_ahb_pdma registers write permission in ree0 mode.\\ 0: can not be write \\ 1: can be write \\
  [4] WRITE_TEE_LP_AHB_PDMA — Configures lp_ahb_pdma registers write permission in tee mode.\\ 0: can not be write \\ 1: can be write \\
  [3] READ_REE2_LP_AHB_PDMA — Configures lp_ahb_pdma registers read permission in ree2 mode.\\ 0: can not be read \\ 1: can be read \\
  [2] READ_REE1_LP_AHB_PDMA — Configures lp_ahb_pdma registers read permission in ree1 mode.\\ 0: can not be read \\ 1: can be read \\
  [1] READ_REE0_LP_AHB_PDMA — Configures lp_ahb_pdma registers read permission in ree0 mode.\\ 0: can not be read \\ 1: can be read \\
  [0] READ_TEE_LP_AHB_PDMA — Configures lp_ahb_pdma registers read permission in tee mode.\\ 0: can not be read \\ 1: can be read \\
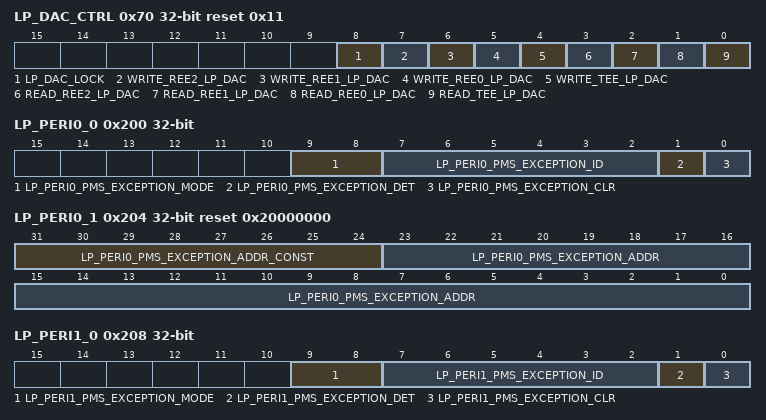
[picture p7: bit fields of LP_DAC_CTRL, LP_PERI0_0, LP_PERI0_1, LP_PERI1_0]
0x70 LP_DAC_CTRL reset 0x11 — lp_dac read/write control register
  [8] LP_DAC_LOCK — Set 1 to lock lp_dac peri_apm configuration
  [7] WRITE_REE2_LP_DAC — Configures lp_dac registers write permission in ree2 mode.\\ 0: can not be write \\ 1: can be write \\
  [6] WRITE_REE1_LP_DAC — Configures lp_dac registers write permission in ree1 mode.\\ 0: can not be write \\ 1: can be write \\
  [5] WRITE_REE0_LP_DAC — Configures lp_dac registers write permission in ree0 mode.\\ 0: can not be write \\ 1: can be write \\
  [4] WRITE_TEE_LP_DAC — Configures lp_dac registers write permission in tee mode.\\ 0: can not be write \\ 1: can be write \\
  [3] READ_REE2_LP_DAC — Configures lp_dac registers read permission in ree2 mode.\\ 0: can not be read \\ 1: can be read \\
  [2] READ_REE1_LP_DAC — Configures lp_dac registers read permission in ree1 mode.\\ 0: can not be read \\ 1: can be read \\
  [1] READ_REE0_LP_DAC — Configures lp_dac registers read permission in ree0 mode.\\ 0: can not be read \\ 1: can be read \\
  [0] READ_TEE_LP_DAC — Configures lp_dac registers read permission in tee mode.\\ 0: can not be read \\ 1: can be read \\
0x200 LP_PERI0_0 access per field — LP_PERI0 PMS configuration & info register
  [9:8] LP_PERI0_PMS_EXCEPTION_MODE ro — Represents the security mode when lp_peri0 pms has been triggered.\\
  [7:2] LP_PERI0_PMS_EXCEPTION_ID ro — Represents the master id when lp_peri0 pms has been triggered.\\
  [1] LP_PERI0_PMS_EXCEPTION_DET ro — Represents whether the lp_peri0 pms has been triggered.\\ 0: No triggered\\ 1: Has been triggered\\
  [0] LP_PERI0_PMS_EXCEPTION_CLR wo — Configures whether or not to clear lp_peri0 peri_pms_record_reg.\\ 0: No clear\\ 1: Clear peri_pms_record_reg\\
0x204 LP_PERI0_1 ro reset 0x20000000 — LP_PERI0 PMS exception addr record register
  [31:24] LP_PERI0_PMS_EXCEPTION_ADDR_CONST — Represents the access address (bit31~bit28) when lp_peri0 pms has been triggered.\\
  [23:0] LP_PERI0_PMS_EXCEPTION_ADDR — Represents the access address (bit27~bit0) when lp_peri0 pms has been triggered.\\
0x208 LP_PERI1_0 access per field — LP_PERI1 PMS configuration & info register
  [9:8] LP_PERI1_PMS_EXCEPTION_MODE ro — Represents the security mode when lp_peri1 pms has been triggered.\\
  [7:2] LP_PERI1_PMS_EXCEPTION_ID ro — Represents the master id when lp_peri1 pms has been triggered.\\
  [1] LP_PERI1_PMS_EXCEPTION_DET ro — Represents whether the lp_peri1 pms has been triggered.\\ 0: No triggered\\ 1: Has been triggered\\
  [0] LP_PERI1_PMS_EXCEPTION_CLR wo — Configures whether or not to clear lp_peri1 peri_pms_record_reg.\\ 0: No clear\\ 1: Clear peri_pms_record_reg\\
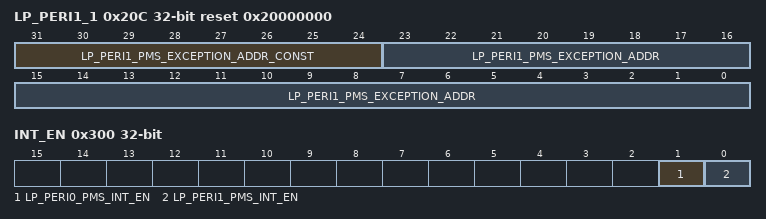
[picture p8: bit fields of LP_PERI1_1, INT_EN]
0x20C LP_PERI1_1 ro reset 0x20000000 — LP_PERI1 PMS exception addr record register
  [31:24] LP_PERI1_PMS_EXCEPTION_ADDR_CONST — Represents the access address (bit31~bit28) when lp_peri1 pms has been triggered.\\
  [23:0] LP_PERI1_PMS_EXCEPTION_ADDR — Represents the access address (bit27~bit0) when lp_peri1 pms has been triggered.\\
0x300 INT_EN — APM interrupt enable register
  [1] LP_PERI0_PMS_INT_EN — Configures to enable lp_peri0 pms interrupt.\\ 0: disable \\ 1: enable \\
  [0] LP_PERI1_PMS_INT_EN — Configures to enable lp_peri1 pms interrupt.\\ 0: disable \\ 1: enable \\
0x7F0 BUS_ERR_CONF — Clock gating register
  [0] BUS_ERR_RESP_EN — Configures whether return error response to cpu when access blocked 0: disable error response \\ 1: enable error response \\
0x7F8 CLOCK_GATE reset 0x1 — Clock gating register
  [0] CLK_EN — Configures whether to keep the clock always on.\\ 0: enable automatic clock gating \\ 1: keep the clock always on \\
0x7FC DATE reset 0x2509240 — Version control register
  [27:0] DATE
